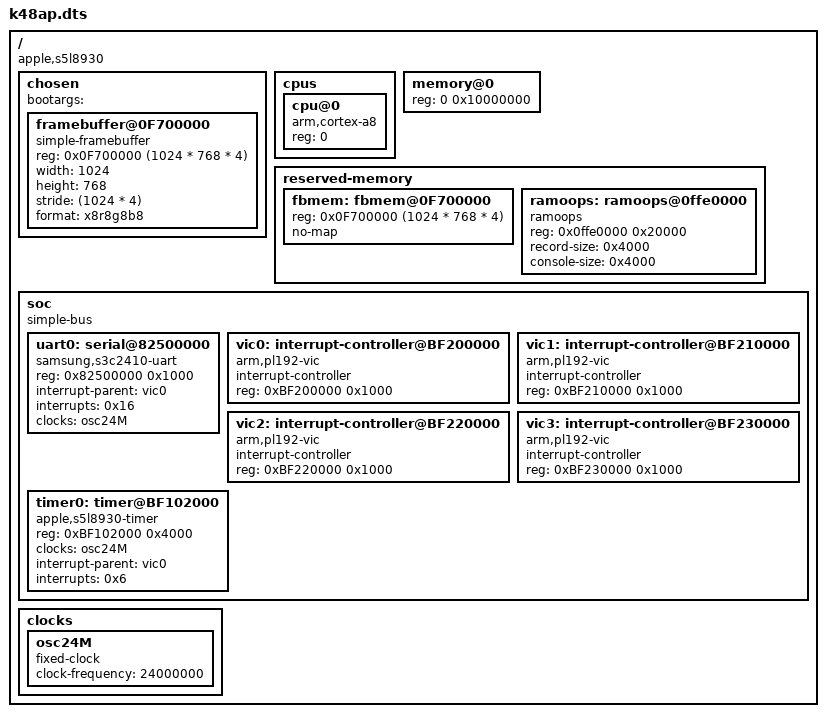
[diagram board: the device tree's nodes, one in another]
// SPDX-License-Identifier: GPL-2.0
/*
 * K48AP - Apple iPad 1
 *
 * Copyright (c) 2018 Joey Hewitt
 *
 */

/dts-v1/;

/ {
	compatible = "apple,s5l8930";

	#address-cells = <1>;
	#size-cells = <1>;

	chosen {
		#address-cells = <1>;
		#size-cells = <1>;
		ranges;

		bootargs = " "; /* XXX testing */

		framebuffer@0F700000 {
			compatible = "simple-framebuffer";
			reg = <0x0F700000 (1024 * 768 * 4)>; // see reserved-memory: fbmem
			width = <1024>;
			height = <768>;
			stride = <(1024 * 4)>;
			format = "x8r8g8b8";
		};
	};

	cpus {
		#address-cells = <1>;
		#size-cells = <0>;

		cpu@0 {
			device_type = "cpu";
			compatible = "arm,cortex-a8";
			reg = <0>;
		};
	};

	memory@0 {
		device_type = "memory";
		reg = <0 0x10000000>;
	};

	reserved-memory {
		#address-cells = <1>;
		#size-cells = <1>;
		ranges;

		fbmem: fbmem@0F700000 {
			reg = <0x0F700000 (1024 * 768 * 4)>;
			no-map;
		};

		ramoops: ramoops@0ffe0000 {
			compatible = "ramoops";
			reg = <0x0ffe0000 0x20000>; // 128kB
			record-size = <0x4000>; // 16kB
			console-size = <0x4000>;
		};
	};

	soc {
		compatible = "simple-bus";
		#address-cells = <1>;
		#size-cells = <1>;
		ranges;

		uart0: serial@82500000 {
			compatible = "samsung,s3c2410-uart";
			reg = <0x82500000 0x1000>;
			interrupt-parent = <&vic0>;
			interrupts = <0x16>;
			clocks = <&osc24M>; /* TODO do we also need to set S3C6400_UCON_UCLK0? We have it sort-of working for console output in QEMU, but has a buffering issue that's either in the QEMU impl or here... */
			clock-names = "uart";
		};

		vic0: interrupt-controller@BF200000 {
			compatible = "arm,pl192-vic";
			interrupt-controller;
			reg = <0xBF200000 0x1000>;
			#interrupt-cells = <1>;
		};
		vic1: interrupt-controller@BF210000 {
			compatible = "arm,pl192-vic";
			interrupt-controller;
			reg = <0xBF210000 0x1000>;
			#interrupt-cells = <1>;
		};
		vic2: interrupt-controller@BF220000 {
			compatible = "arm,pl192-vic";
			interrupt-controller;
			reg = <0xBF220000 0x1000>;
			#interrupt-cells = <1>;
		};
		vic3: interrupt-controller@BF230000 {
			compatible = "arm,pl192-vic";
			interrupt-controller;
			reg = <0xBF230000 0x1000>;
			#interrupt-cells = <1>;
		};

		timer0: timer@BF102000 {
			compatible = "apple,s5l8930-timer";
			reg = <0xBF102000 0x4000>;
			clocks = <&osc24M>;
			interrupt-parent = <&vic0>;
			interrupts = <0x6>;
		};

	};

	clocks {
		#address-cells = <1>;
		#size-cells = <1>;
		ranges;

		osc24M: osc24M {
			#clock-cells = <0>;
			compatible = "fixed-clock";
			clock-frequency = <24000000>;
		};
	};
};
